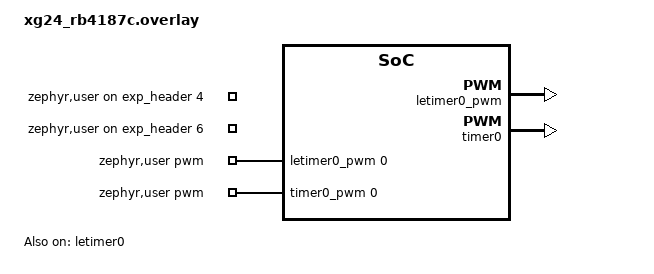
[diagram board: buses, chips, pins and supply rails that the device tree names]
/*
 * Copyright (c) 2025 Silicon Laboratories Inc.
 *
 * SPDX-License-Identifier: Apache-2.0
 */

#include <zephyr/dt-bindings/pwm/pwm.h>

/* Connections:
 * EXP7 - EXP4: LETIMER (PA5) to GPIO (PC1)
 * EXP9 - EXP6: TIMER (PD2) to GPIO (PC2)
 */

/ {
	zephyr,user {
		pwms = <&letimer0_pwm 0 PWM_MSEC(5) PWM_POLARITY_NORMAL>,
		       <&timer0_pwm 0 PWM_MSEC(5) PWM_POLARITY_NORMAL>;
		gpios = <&exp_header 4 GPIO_ACTIVE_HIGH>, <&exp_header 6 GPIO_ACTIVE_HIGH>;
	};
};

&pinctrl {
	letimer0_default: letimer0_default {
		group1 {
			pins = <LETIMER0_OUT0_PA5>;
			drive-push-pull;
		};
	};

	timer0_default: timer0_default {
		group1 {
			pins = <TIMER0_CC0_PD2>;
			drive-push-pull;
		};
	};
};

&letimer0 {
	status = "okay";

	letimer0_pwm: pwm {
		pinctrl-0 = <&letimer0_default>;
		pinctrl-names = "default";
		status = "okay";
	};
};

&timer0 {
	status = "okay";

	timer0_pwm: pwm {
		pinctrl-0 = <&timer0_default>;
		pinctrl-names = "default";
		status = "okay";
	};
};
